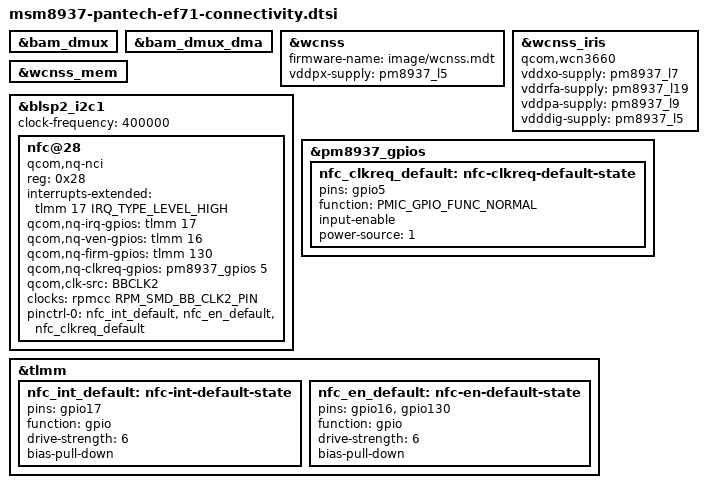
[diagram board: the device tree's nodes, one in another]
// SPDX-License-Identifier: GPL-2.0-only
/*
 * EF71 connectivity: WCNSS (WCN3660 Wi-Fi/Bluetooth/FM), BAM-DMUX
 * for mobile data and the PN548 NFC controller.
 *
 * Copyright (c) 2026, hiru <rlawoehd187@naver.com>
 */

#include <dt-bindings/clock/qcom,rpmcc.h>
#include <dt-bindings/gpio/gpio.h>
#include <dt-bindings/interrupt-controller/irq.h>
#include <dt-bindings/pinctrl/qcom,pmic-gpio.h>

&bam_dmux {
	status = "okay";
};

&bam_dmux_dma {
	status = "okay";
};

&wcnss {
	firmware-name = "image/wcnss.mdt";
	vddpx-supply = <&pm8937_l5>;

	status = "okay";
};

/* IRIS 0x0400: WCN3660, dual band */
&wcnss_iris {
	compatible = "qcom,wcn3660";
	vddxo-supply = <&pm8937_l7>;
	vddrfa-supply = <&pm8937_l19>;
	vddpa-supply = <&pm8937_l9>;
	vdddig-supply = <&pm8937_l5>;
};

&wcnss_mem {
	status = "okay";
};

/*
 * PN548 NFC controller, driven by the nq-nci char driver the Android NFC
 * HAL opens as /dev/nq-nci. BB_CLK2 runs in pin control mode and follows
 * the controller's clock request on PM8937 GPIO 5, so that pin has to be
 * set up as an input or the PN548 resets as soon as it turns its field on.
 */
&blsp2_i2c1 {
	status = "okay";
	clock-frequency = <400000>;

	nfc@28 {
		compatible = "qcom,nq-nci";
		reg = <0x28>;

		interrupts-extended = <&tlmm 17 IRQ_TYPE_LEVEL_HIGH>;
		interrupt-names = "nfc_irq";

		qcom,nq-irq-gpios = <&tlmm 17 GPIO_ACTIVE_HIGH>;
		qcom,nq-ven-gpios = <&tlmm 16 GPIO_ACTIVE_HIGH>;
		qcom,nq-firm-gpios = <&tlmm 130 GPIO_ACTIVE_HIGH>;
		qcom,nq-clkreq-gpios = <&pm8937_gpios 5 GPIO_ACTIVE_HIGH>;
		qcom,clk-src = "BBCLK2";

		clocks = <&rpmcc RPM_SMD_BB_CLK2_PIN>;
		clock-names = "ref_clk";

		pinctrl-0 = <&nfc_int_default &nfc_en_default &nfc_clkreq_default>;
		pinctrl-names = "default";
	};
};

&pm8937_gpios {
	nfc_clkreq_default: nfc-clkreq-default-state {
		pins = "gpio5";
		function = PMIC_GPIO_FUNC_NORMAL;
		input-enable;
		power-source = <1>;
	};
};

&tlmm {
	nfc_int_default: nfc-int-default-state {
		pins = "gpio17";
		function = "gpio";
		drive-strength = <6>;
		bias-pull-down;
	};

	nfc_en_default: nfc-en-default-state {
		pins = "gpio16", "gpio130";
		function = "gpio";
		drive-strength = <6>;
		bias-pull-down;
	};
};
